# PIC32MX664F064L device description
Architecture: MIPS; Family: PIC32MX; Series: PIC32MX
Registers are 32-bit, read-write, no defined reset value unless marked. A register's access mark holds for its fields unless they carry their own. Offsets are from the block's base; [hi:lo] are bit positions; 'fields as' and 'values as' point back to an identical list.

## I2C
Instances: I2C 0x1f804ff4 in periph0
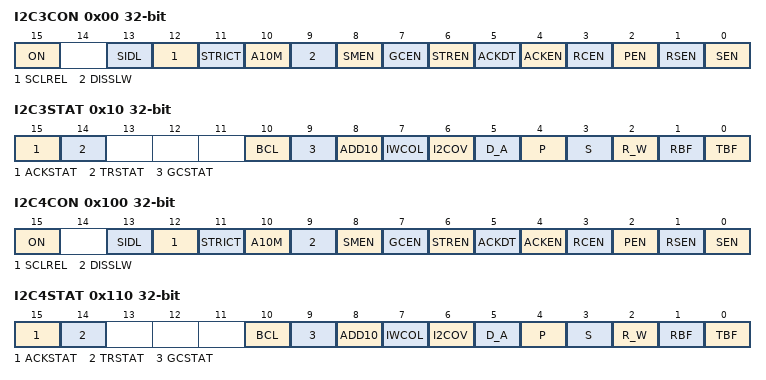
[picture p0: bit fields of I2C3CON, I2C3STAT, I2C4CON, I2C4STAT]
0x00 I2C3CON — I2C Control Register
  [15] ON — I2C Enable bit
    1=Enables the I2C module and configures the SDA and SCL pins as serial port pins; 0=Disables the I2C module; all I2C pins are controlled by PORT functions
  [13] SIDL — Stop in Idle Mode bit
    1=Discontinue module operation when device enters Idle mode; 0=Continue module operation in Idle mode
  [12] SCLREL — SCLx Release Control bit (when operating as I2C slave)
    1=Release SCLx clock; 0=Hold SCLx clock low (clock stretch)
  [11] STRICT — Strict I 2 C Reserved Address Rule Enable bit
    1=Strict reserved addressing is enforced. Device does not respond to reserved address space or generate addresses in reserved address space.; 0=Strict I2C Reserved Address Rule is not enabled
  [10] A10M — 10-bit Slave Address bit
    1=I2CxADD is a 10-bit slave address; 0=I2CxADD is a 7-bit slave address
  [9] DISSLW — Disable Slew Rate Control bit
    1=Slew rate control is disabled; 0=Slew rate control is enabled
  [8] SMEN — SMBus Input Levels bit
    1=Enable I/O pin thresholds compliant with SMBus specification; 0=Disable SMBus input thresholds
  [7] GCEN — General Call Enable bit (when operating as I2C slave)
    1=Enable interrupt when a general call address is received in the I2CxRSR(module is enabled for reception); 0=General call address disabled
  [6] STREN — SCLx Clock Stretch Enable bit (when operating as I2C slave)
    1=Enable software or receive clock stretching; 0=Disable software or receive clock stretching
  [5] ACKDT — Acknowledge Data bit (when operating as I2C master, applicable during master receive)
    1=Send NACK during Acknowledge; 0=Send ACK during Acknowledge
  [4] ACKEN — Acknowledge Sequence Enable bit
    1=Initiate Acknowledge sequence on SDAx and SCLx pins and transmit ACKDT data bit. Hardware clear at end of master Acknowledge sequence.; 0=Acknowledge sequence not in progress
  [3] RCEN — Receive Enable bit (when operating as I2C master)
    1=Enables Receive mode for I2C. Hardware clear at end of eighth bit of master receive data byte.; 0=Receive sequence not in progress
  [2] PEN — Stop Condition Enable bit (when operating as I2C master)
    1=Initiate Stop condition on SDAx and SCLx pins. Hardware clear at end of master Stop sequence.; 0=Stop condition not in progress
  [1] RSEN — Repeated Start Condition Enable bit (when operating as I2C master)
    1=Initiate Repeated Start condition on SDAx and SCLx pins. Hardware clear at end of master Repeated Start sequence.; 0=Repeated Start condition not in progress
  [0] SEN — Start Condition Enable bit (when operating as I2C master)
    1=Initiate Start condition on SDAx and SCLx pins. Hardware clear at end of master Start sequence.; 0=Start condition not in progress
0x10 I2C3STAT ro — I2C Status Register
  [15] ACKSTAT — Acknowledge Status bit (when operating as I2C master, applicable to master transmit operation)
    1=Acknowledge was not received from slave; 0=Acknowledge was received from slave
  [14] TRSTAT — Transmit Status bit (when operating as I2C master, applicable to master transmit operation)
    1=Master transmit is in progress (8 bits + ACK); 0=Master transmit is not in progress
  [10] BCL — Master Bus Collision Detect bit
    1=A bus collision has been detected during a master operation; 0=No collision
  [9] GCSTAT — General Call Status bit
    1=General call address was received; 0=General call address was not received
  [8] ADD10 — 10-bit Address Status bit
    1=10-bit address was matched; 0=10-bit address was not matched
  [7] IWCOL — Write Collision Detect bit
    1=An attempt to write the I2CxTRN register failed because the I2C module is busy; 0=No collision
  [6] I2COV — Receive Overflow Flag bit
    1=A byte was received while the I2CxRCV register is still holding the previous byte; 0=No overflow
  [5] D_A — Data/Address bit (when operating as I2C slave)
    1=Indicates that the last byte received was data; 0=Indicates that the last byte received was device address
  [4] P — Stop bit
    1=Indicates that a Stop bit has been detected last; 0=Stop bit was not detected last
  [3] S — Start bit
    1=Indicates that a Start (or Repeated Start) bit has been detected last; 0=Start bit was not detected last
  [2] R_W — Read/Write Information bit (when operating as I2C slave)
    1=Read indicates data transfer is output from slave; 0=Write indicates data transfer is input to slave
  [1] RBF — Receive Buffer Full Status bit
    1=Receive complete I2CxRCV is full; 0=Receive not complete I2CxRCV is empty
  [0] TBF — Transmit Buffer Full Status bit
    1=Transmit in progress I2CxTRN is full; 0=Transmit complete I2CxTRN is empty
0x20 I2C3ADD
  [9:0] I2CADD
0x30 I2C3MSK
  [9:0] I2CMSK
0x40 I2C3BRG
  [11:0] I2CBRG
0x50 I2C3TRN
  [7:0] I2CTRN
0x60 I2C3RCV
  [7:0] I2CRCV
0x100 I2C4CON — I2C Control Register
  fields as I2C3CON
0x110 I2C4STAT ro — I2C Status Register
  fields as I2C3STAT
0x120 I2C4ADD
  [9:0] I2CADD
0x130 I2C4MSK
  [9:0] I2CMSK
0x140 I2C4BRG
  [11:0] I2CBRG
0x150 I2C4TRN
  [7:0] I2CTRN
0x160 I2C4RCV
  [7:0] I2CRCV
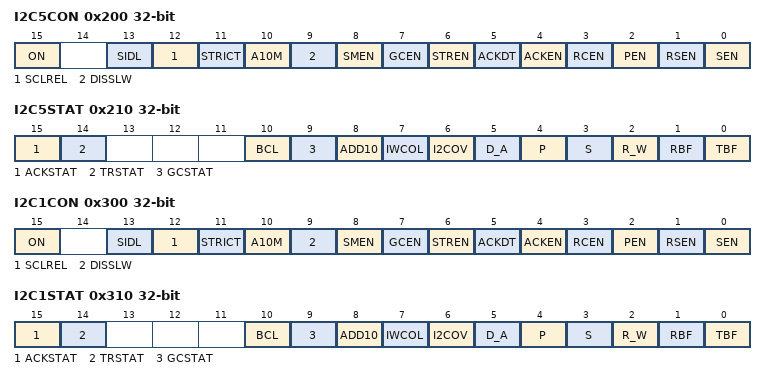
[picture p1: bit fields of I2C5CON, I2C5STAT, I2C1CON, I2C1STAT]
0x200 I2C5CON — I2C Control Register
  fields as I2C3CON
0x210 I2C5STAT ro — I2C Status Register
  fields as I2C3STAT
0x220 I2C5ADD
  [9:0] I2CADD
0x230 I2C5MSK
  [9:0] I2CMSK
0x240 I2C5BRG
  [11:0] I2CBRG
0x250 I2C5TRN
  [7:0] I2CTRN
0x260 I2C5RCV
  [7:0] I2CRCV
0x300 I2C1CON — I2C Control Register
  fields as I2C3CON
0x310 I2C1STAT ro — I2C Status Register
  fields as I2C3STAT
0x320 I2C1ADD
  [9:0] I2CADD
0x330 I2C1MSK
  [9:0] I2CMSK
0x340 I2C1BRG
  [11:0] I2CBRG
0x350 I2C1TRN
  [7:0] I2CTRN
0x360 I2C1RCV
  [7:0] I2CRCV
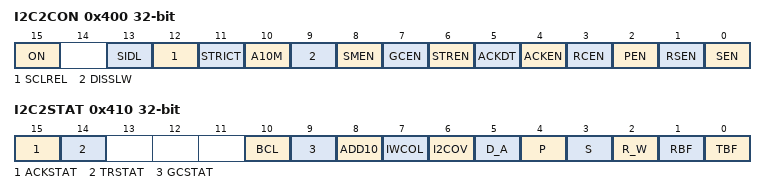
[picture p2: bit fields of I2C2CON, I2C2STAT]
0x400 I2C2CON — I2C Control Register
  fields as I2C3CON
0x410 I2C2STAT ro — I2C Status Register
  fields as I2C3STAT
0x420 I2C2ADD
  [9:0] I2CADD
0x430 I2C2MSK
  [9:0] I2CMSK
0x440 I2C2BRG
  [11:0] I2CBRG
0x450 I2C2TRN
  [7:0] I2CTRN
0x460 I2C2RCV
  [7:0] I2CRCV

## Notices in the file
Copyright (c) 2019 Microchip Technology Inc.
SPDX-License-Identifier: Apache-2.0
Licensed under the Apache License, Version 2.0 (the "License");
you may not use this file except in compliance with the License.
You may obtain a copy of the License at
http://www.apache.org/licenses/LICENSE-2.0
Unless required by applicable law or agreed to in writing, software
distributed under the License is distributed on an "AS IS" BASIS,
WITHOUT WARRANTIES OR CONDITIONS OF ANY KIND, either express or implied.
See the License for the specific language governing permissions and
limitations under the License.
